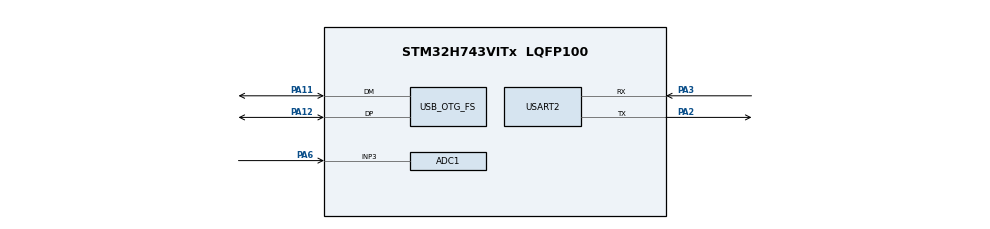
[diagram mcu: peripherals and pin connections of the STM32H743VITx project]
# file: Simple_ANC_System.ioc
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ADC1.Channel-0\#ChannelRegularConversion=ADC_CHANNEL_3
ADC1.ContinuousConvMode=ENABLE
ADC1.ConversionDataManagement=ADC_CONVERSIONDATA_DMA_CIRCULAR
ADC1.NbrOfConversionFlag=1
ADC1.OffsetNumber-0\#ChannelRegularConversion=ADC_OFFSET_NONE
ADC1.OffsetSignedSaturation-0\#ChannelRegularConversion=DISABLE
ADC1.Rank-0\#ChannelRegularConversion=1
ADC1.SamplingTime-0\#ChannelRegularConversion=ADC_SAMPLETIME_16CYCLES_5
ADC1.master=1
Dma.ADC1.0.Direction=DMA_PERIPH_TO_MEMORY
Dma.ADC1.0.EventEnable=DISABLE
Dma.ADC1.0.FIFOMode=DMA_FIFOMODE_DISABLE
Dma.ADC1.0.Instance=DMA1_Stream0
Dma.ADC1.0.MemDataAlignment=DMA_MDATAALIGN_HALFWORD
Dma.ADC1.0.MemInc=DMA_MINC_ENABLE
Dma.ADC1.0.Mode=DMA_CIRCULAR
Dma.ADC1.0.PeriphDataAlignment=DMA_PDATAALIGN_HALFWORD
Dma.ADC1.0.PeriphInc=DMA_PINC_DISABLE
Dma.ADC1.0.Polarity=HAL_DMAMUX_REQ_GEN_RISING
Dma.ADC1.0.Priority=DMA_PRIORITY_LOW
Dma.ADC1.0.RequestNumber=1
Dma.ADC1.0.SignalID=NONE
Dma.ADC1.0.SyncEnable=DISABLE
Dma.ADC1.0.SyncPolarity=HAL_DMAMUX_SYNC_NO_EVENT
Dma.ADC1.0.SyncRequestNumber=1
Dma.ADC1.0.SyncSignalID=NONE
Dma.Request0=ADC1
Mcu.Family=STM32H7
Mcu.Name=STM32H743VITx
Mcu.Package=LQFP100
NVIC.ADC_IRQn=true\:0\:0\:false\:false\:true\:true\:true\:true
NVIC.DMA1_Stream0_IRQn=true\:0\:0\:false\:false\:true\:false\:true\:true
NVIC.OTG_FS_IRQn=true\:0\:0\:false\:false\:true\:false\:true\:true
NVIC.PriorityGroup=NVIC_PRIORITYGROUP_4
PA11.Mode=Device_Only
PA11.Signal=USB_OTG_FS_DM
PA12.Mode=Device_Only
PA12.Signal=USB_OTG_FS_DP
PA2.Mode=Asynchronous
PA2.Signal=USART2_TX
PA3.Mode=Asynchronous
PA3.Signal=USART2_RX
PA6.Signal=ADCx_INP3
PH0-OSC_IN\ (PH0).Mode=HSE-External-Oscillator
PH0-OSC_IN\ (PH0).Signal=RCC_OSC_IN
PH1-OSC_OUT\ (PH1).Mode=HSE-External-Oscillator
PH1-OSC_OUT\ (PH1).Signal=RCC_OSC_OUT
ProjectManager.HeapSize=0x200
ProjectManager.StackSize=0x400
ProjectManager.TargetToolchain=STM32CubeIDE
RCC.ADCFreq_Value=75000000
RCC.APB1Freq_Value=64000000
RCC.APB2Freq_Value=64000000
RCC.APB3Freq_Value=64000000
RCC.APB4Freq_Value=64000000
RCC.CortexFreq_Value=64000000
RCC.DIVM1=5
RCC.DIVM2=2
RCC.DIVM3=30
RCC.DIVN1=48
RCC.DIVN2=12
RCC.DIVN3=100
RCC.DIVQ1=5
RCC.DIVQ3=5
RCC.HCLKFreq_Value=64000000
RCC.PLL2FRACN=0
RCC.PLL3FRACN=0
RCC.PLLFRACN=0
RCC.SYSCLKFreq_VALUE=64000000
RCC.USART234578CLockSelection=RCC_USART234578CLKSOURCE_CSI
RCC.USBFreq_Value=48000000
SH.ADCx_INP3.0=ADC1_INP3,IN3-Single-Ended
USART2.VirtualMode-Asynchronous=VM_ASYNC
USB_DEVICE.CLASS_NAME_FS=CDC
USB_DEVICE.VirtualMode-CDC_FS=Cdc
USB_DEVICE.VirtualModeFS=Cdc_FS
USB_OTG_FS.VirtualMode=Device_Only
VP_MEMORYMAP_VS_MEMORYMAP.Mode=CurAppReg
VP_USB_DEVICE_VS_USB_DEVICE_CDC_FS.Mode=CDC_FS
board=custom

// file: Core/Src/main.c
/* USER CODE BEGIN Header */
/**
  ******************************************************************************
  * @file           : main.c
  * @brief          : Main program body
  ******************************************************************************
  * @attention
  *
  * Copyright (c) 2025 STMicroelectronics.
  * All rights reserved.
  *
  * This software is licensed under terms that can be found in the LICENSE file
  * in the root directory of this software component.
  * If no LICENSE file comes with this software, it is provided AS-IS.
  *
  ******************************************************************************
  */
/* USER CODE END Header */
#include "main.h"
#include "usb_device.h"

/* USER CODE BEGIN Includes */
#include "usbd_cdc_if.h"
#include <stdio.h>
#include <string.h>
/* USER CODE END Includes */

/* USER CODE BEGIN PD */
#define adc_buff_size 2048
/* USER CODE END PD */

ADC_HandleTypeDef hadc1;
DMA_HandleTypeDef hdma_adc1;

UART_HandleTypeDef huart2;

void SystemClock_Config(void);
static void MX_GPIO_Init(void);
static void MX_DMA_Init(void);
static void MX_ADC1_Init(void);
static void MX_USART2_UART_Init(void);

/* USER CODE BEGIN 0 */

uint16_t ADC_Buff[adc_buff_size];

volatile uint8_t adc_half_ready = 0;
volatile uint8_t adc_full_ready = 0;

/* USER CODE BEGIN 4 */

void HAL_ADC_ConvHalfCpltCallback(ADC_HandleTypeDef* hadc)
{
    if (hadc->Instance == ADC1)
    {
        adc_half_ready = 1;
    }
}

void HAL_ADC_ConvCpltCallback(ADC_HandleTypeDef* hadc)
{
    if (hadc->Instance == ADC1)
    {
        adc_full_ready = 1;
    }
}

/* USER CODE END 4 */

/* USER CODE END 0 */

int main(void)
{

  /* MCU Configuration--------------------------------------------------------*/

  /* Reset of all peripherals, Initializes the Flash interface and the Systick. */
  HAL_Init();

  /* Configure the system clock */
  SystemClock_Config();

  /* Initialize all configured peripherals */
  MX_GPIO_Init();
  MX_DMA_Init();
  MX_ADC1_Init();
  MX_USART2_UART_Init();
  MX_USB_DEVICE_Init();
  /* USER CODE BEGIN 2 */

  HAL_ADC_Start_DMA(&hadc1, (uint32_t *)ADC_Buff, adc_buff_size);

  /* USER CODE END 2 */

  /* Infinite loop */
  while (1)
  {

	  // Half buffer ready
	  if (adc_half_ready)
	  {
		  adc_half_ready = 0;

		  // Cast to bytes and send ADC_BUF_LEN/2 samples
		  uint8_t *ptr = (uint8_t*)&ADC_Buff[0];
		  uint16_t len_bytes = (adc_buff_size / 2) * sizeof(uint16_t); //devide by 2 bcz use 2 bytes in one sample

		  // Wait until USB CDC is ready
		  if (CDC_Transmit_FS(ptr, len_bytes) == USBD_OK)
		  {
			  // sent successfully
		  }
		  // else: you can retry or drop
	  }

	  // Full buffer ready
	  if (adc_full_ready)
	  {
		  adc_full_ready = 0;

		  uint8_t *ptr = (uint8_t*)&ADC_Buff[adc_buff_size / 2];
		  uint16_t len_bytes = (adc_buff_size / 2) * sizeof(uint16_t);

		  if (CDC_Transmit_FS(ptr, len_bytes) == USBD_OK)
		  {
			  // sent successfully
		  }
	  }

	  // add a small delay if needed
//	   HAL_Delay(1);

  }
}

void SystemClock_Config(void)
{
  RCC_OscInitTypeDef RCC_OscInitStruct = {0};
  RCC_ClkInitTypeDef RCC_ClkInitStruct = {0};

  /** Supply configuration update enable
  */
  HAL_PWREx_ConfigSupply(PWR_LDO_SUPPLY);

  /** Configure the main internal regulator output voltage
  */
  __HAL_PWR_VOLTAGESCALING_CONFIG(PWR_REGULATOR_VOLTAGE_SCALE3);

  while(!__HAL_PWR_GET_FLAG(PWR_FLAG_VOSRDY)) {}

  /** Initializes the RCC Oscillators according to the specified parameters
  * in the RCC_OscInitTypeDef structure.
  */
  RCC_OscInitStruct.OscillatorType = RCC_OSCILLATORTYPE_CSI|RCC_OSCILLATORTYPE_HSI
                              |RCC_OSCILLATORTYPE_HSE;
  RCC_OscInitStruct.HSEState = RCC_HSE_ON;
  RCC_OscInitStruct.HSIState = RCC_HSI_DIV1;
  RCC_OscInitStruct.HSICalibrationValue = RCC_HSICALIBRATION_DEFAULT;
  RCC_OscInitStruct.CSIState = RCC_CSI_ON;
  RCC_OscInitStruct.CSICalibrationValue = RCC_CSICALIBRATION_DEFAULT;
  RCC_OscInitStruct.PLL.PLLState = RCC_PLL_ON;
  RCC_OscInitStruct.PLL.PLLSource = RCC_PLLSOURCE_HSE;
  RCC_OscInitStruct.PLL.PLLM = 5;
  RCC_OscInitStruct.PLL.PLLN = 48;
  RCC_OscInitStruct.PLL.PLLP = 2;
  RCC_OscInitStruct.PLL.PLLQ = 5;
  RCC_OscInitStruct.PLL.PLLR = 2;
  RCC_OscInitStruct.PLL.PLLRGE = RCC_PLL1VCIRANGE_2;
  RCC_OscInitStruct.PLL.PLLVCOSEL = RCC_PLL1VCOWIDE;
  RCC_OscInitStruct.PLL.PLLFRACN = 0;
  if (HAL_RCC_OscConfig(&RCC_OscInitStruct) != HAL_OK)
  {
    Error_Handler();
  }

  /** Initializes the CPU, AHB and APB buses clocks
  */
  RCC_ClkInitStruct.ClockType = RCC_CLOCKTYPE_HCLK|RCC_CLOCKTYPE_SYSCLK
                              |RCC_CLOCKTYPE_PCLK1|RCC_CLOCKTYPE_PCLK2
                              |RCC_CLOCKTYPE_D3PCLK1|RCC_CLOCKTYPE_D1PCLK1;
  RCC_ClkInitStruct.SYSCLKSource = RCC_SYSCLKSOURCE_HSI;
  RCC_ClkInitStruct.SYSCLKDivider = RCC_SYSCLK_DIV1;
  RCC_ClkInitStruct.AHBCLKDivider = RCC_HCLK_DIV1;
  RCC_ClkInitStruct.APB3CLKDivider = RCC_APB3_DIV1;
  RCC_ClkInitStruct.APB1CLKDivider = RCC_APB1_DIV1;
  RCC_ClkInitStruct.APB2CLKDivider = RCC_APB2_DIV1;
  RCC_ClkInitStruct.APB4CLKDivider = RCC_APB4_DIV1;

  if (HAL_RCC_ClockConfig(&RCC_ClkInitStruct, FLASH_LATENCY_1) != HAL_OK)
  {
    Error_Handler();
  }
}

static void MX_ADC1_Init(void)
{

  ADC_MultiModeTypeDef multimode = {0};
  ADC_ChannelConfTypeDef sConfig = {0};

  /** Common config
  */
  hadc1.Instance = ADC1;
  hadc1.Init.ClockPrescaler = ADC_CLOCK_ASYNC_DIV2;
  hadc1.Init.Resolution = ADC_RESOLUTION_16B;
  hadc1.Init.ScanConvMode = ADC_SCAN_DISABLE;
  hadc1.Init.EOCSelection = ADC_EOC_SINGLE_CONV;
  hadc1.Init.LowPowerAutoWait = DISABLE;
  hadc1.Init.ContinuousConvMode = ENABLE;
  hadc1.Init.NbrOfConversion = 1;
  hadc1.Init.DiscontinuousConvMode = DISABLE;
  hadc1.Init.ExternalTrigConv = ADC_SOFTWARE_START;
  hadc1.Init.ExternalTrigConvEdge = ADC_EXTERNALTRIGCONVEDGE_NONE;
  hadc1.Init.ConversionDataManagement = ADC_CONVERSIONDATA_DMA_CIRCULAR;
  hadc1.Init.Overrun = ADC_OVR_DATA_PRESERVED;
  hadc1.Init.LeftBitShift = ADC_LEFTBITSHIFT_NONE;
  hadc1.Init.OversamplingMode = DISABLE;
  hadc1.Init.Oversampling.Ratio = 1;
  if (HAL_ADC_Init(&hadc1) != HAL_OK)
  {
    Error_Handler();
  }

  /** Configure the ADC multi-mode
  */
  multimode.Mode = ADC_MODE_INDEPENDENT;
  if (HAL_ADCEx_MultiModeConfigChannel(&hadc1, &multimode) != HAL_OK)
  {
    Error_Handler();
  }

  /** Configure Regular Channel
  */
  sConfig.Channel = ADC_CHANNEL_3;
  sConfig.Rank = ADC_REGULAR_RANK_1;
  sConfig.SamplingTime = ADC_SAMPLETIME_16CYCLES_5;
  sConfig.SingleDiff = ADC_SINGLE_ENDED;
  sConfig.OffsetNumber = ADC_OFFSET_NONE;
  sConfig.Offset = 0;
  sConfig.OffsetSignedSaturation = DISABLE;
  if (HAL_ADC_ConfigChannel(&hadc1, &sConfig) != HAL_OK)
  {
    Error_Handler();
  }

}

static void MX_USART2_UART_Init(void)
{

  huart2.Instance = USART2;
  huart2.Init.BaudRate = 115200;
  huart2.Init.WordLength = UART_WORDLENGTH_8B;
  huart2.Init.StopBits = UART_STOPBITS_1;
  huart2.Init.Parity = UART_PARITY_NONE;
  huart2.Init.Mode = UART_MODE_TX_RX;
  huart2.Init.HwFlowCtl = UART_HWCONTROL_NONE;
  huart2.Init.OverSampling = UART_OVERSAMPLING_16;
  huart2.Init.OneBitSampling = UART_ONE_BIT_SAMPLE_DISABLE;
  huart2.Init.ClockPrescaler = UART_PRESCALER_DIV1;
  huart2.AdvancedInit.AdvFeatureInit = UART_ADVFEATURE_NO_INIT;
  if (HAL_UART_Init(&huart2) != HAL_OK)
  {
    Error_Handler();
  }
  if (HAL_UARTEx_SetTxFifoThreshold(&huart2, UART_TXFIFO_THRESHOLD_1_8) != HAL_OK)
  {
    Error_Handler();
  }
  if (HAL_UARTEx_SetRxFifoThreshold(&huart2, UART_RXFIFO_THRESHOLD_1_8) != HAL_OK)
  {
    Error_Handler();
  }
  if (HAL_UARTEx_DisableFifoMode(&huart2) != HAL_OK)
  {
    Error_Handler();
  }

}

static void MX_DMA_Init(void)
{

  /* DMA controller clock enable */
  __HAL_RCC_DMA1_CLK_ENABLE();

  /* DMA interrupt init */
  /* DMA1_Stream0_IRQn interrupt configuration */
  HAL_NVIC_SetPriority(DMA1_Stream0_IRQn, 0, 0);
  HAL_NVIC_EnableIRQ(DMA1_Stream0_IRQn);

}

static void MX_GPIO_Init(void)
{

  /* GPIO Ports Clock Enable */
  __HAL_RCC_GPIOH_CLK_ENABLE();
  __HAL_RCC_GPIOA_CLK_ENABLE();

}

void Error_Handler(void)
{
  __disable_irq();
  while (1)
  {
  }
}
